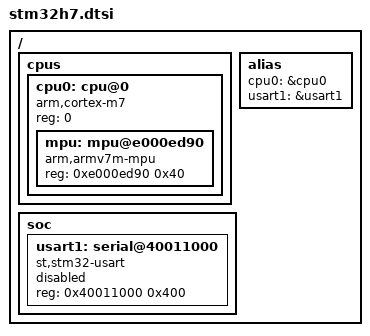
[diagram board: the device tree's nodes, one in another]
/dts-v1/;

/ {
    cpus {
        #address-cells = <1>;
        #size-cells = <0>;

        cpu0: cpu@0 {
            compatible = "arm,cortex-m7";
            device_type = "cpu";
            reg = <0>;
            #address-cells = <1>;
            #size-cells = <1>;

            mpu: mpu@e000ed90 {
                compatible = "arm,armv7m-mpu";
                reg = <0xe000ed90 0x40>;
            };
        };
    };

    alias {
        cpu0 = &cpu0;
        usart1 = &usart1;
    };

    soc {
        #address-cells = <1>;
        #size-cells = <1>;
        usart1: serial@40011000 {
            compatible = "st,stm32-usart", "st,stm32-uart";
            reg = <0x40011000 0x400>;
            status = "disabled";
        };
    };


};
